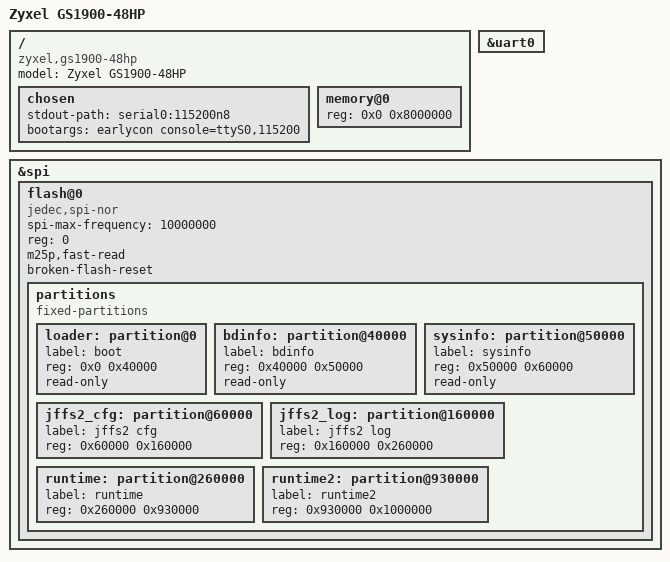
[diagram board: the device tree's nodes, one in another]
// SPDX-License-Identifier: GPL-2.0-or-later OR BSD-2-Clause

/dts-v1/;

#include "rtl83xx.dtsi"
#include "rtl839x.dtsi"
#include "rtl8393.dtsi"

/ {
	model = "Zyxel GS1900-48HP";
	compatible = "zyxel,gs1900-48hp", "realtek,rtl8393-soc";

	chosen {
		stdout-path = "serial0:115200n8";
		bootargs = "earlycon console=ttyS0,115200";
	};

	memory@0 {
		device_type = "memory";
		reg = <0x0 0x8000000>;
	};
};

&uart0 {
	status = "okay";
};

&spi {
	status = "okay";

	flash@0 {
		compatible = "jedec,spi-nor";
		spi-max-frequency = <10000000>;
		reg = <0>;
		m25p,fast-read;
		broken-flash-reset;

		partitions {
			compatible = "fixed-partitions";
			#address-cells = <1>;
			#size-cells = <1>;

			loader: partition@0 {
				label = "boot";
				reg = <0x0 0x40000>;
				read-only;
			};

			bdinfo: partition@40000 {
				label = "bdinfo";
				reg = <0x40000 0x50000>;
				read-only;
			};

			sysinfo: partition@50000 {
				label = "sysinfo";
				reg = <0x50000 0x60000>;
				read-only;
			};

			jffs2_cfg: partition@60000 {
				label = "jffs2 cfg";
				reg = <0x60000 0x160000>;
			};

			jffs2_log: partition@160000 {
				label = "jffs2 log";
				reg = <0x160000 0x260000>;
			};

			runtime: partition@260000 {
				label = "runtime";
				reg = <0x260000 0x930000>;
			};

			runtime2: partition@930000 {
				label = "runtime2";
				reg = <0x930000 0x1000000>;
			};
		};
	};
};
